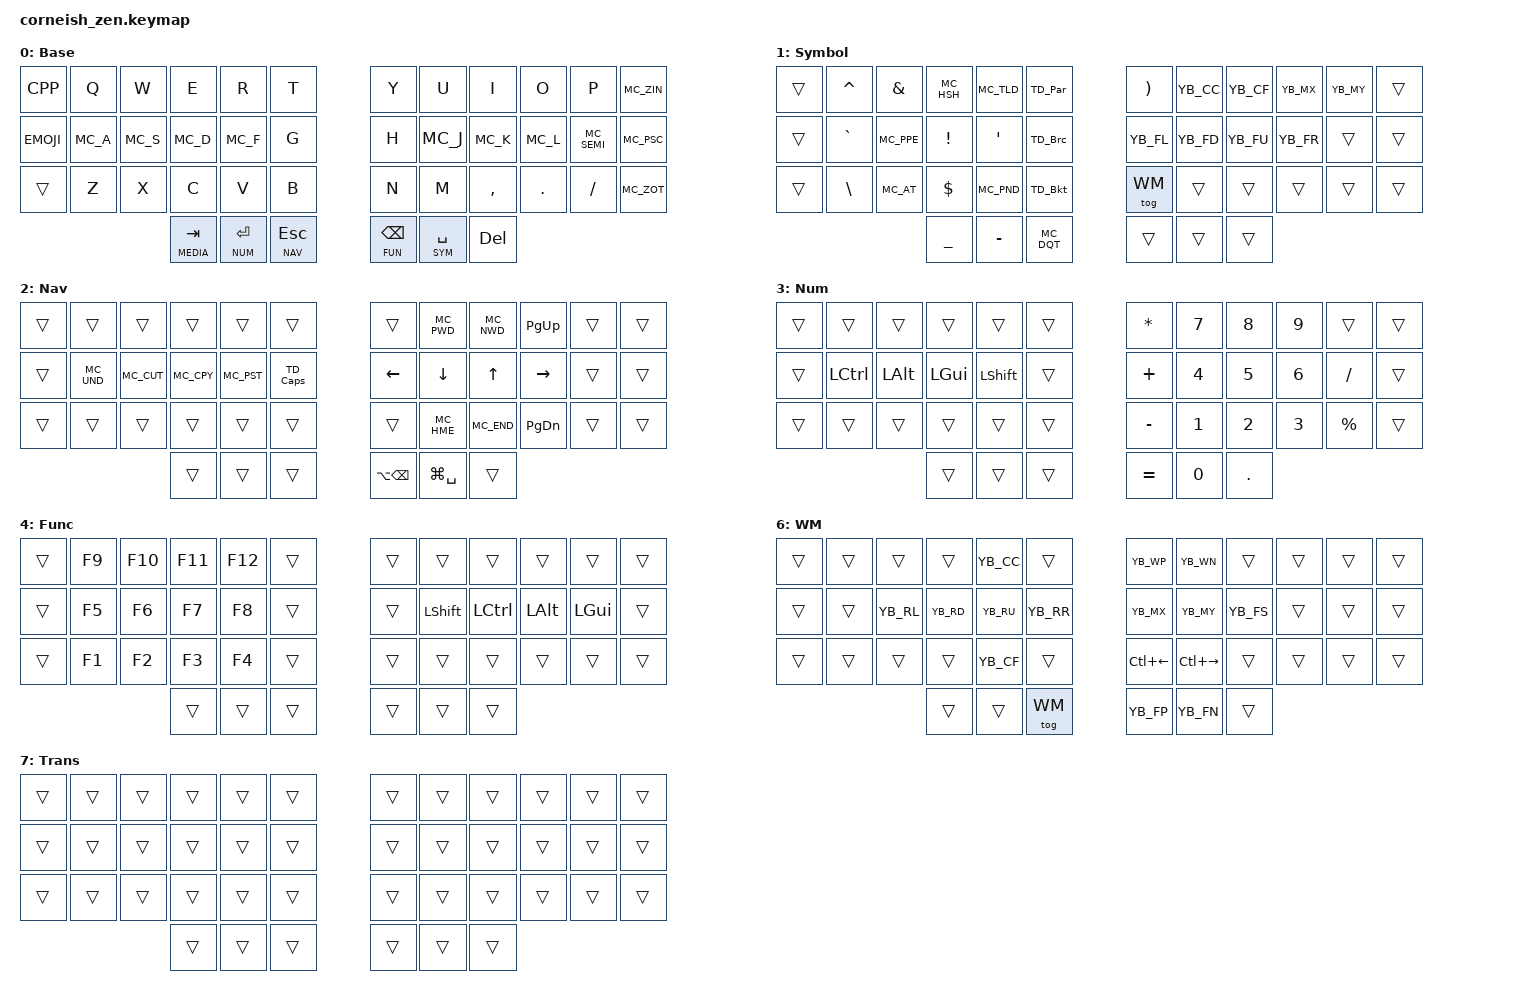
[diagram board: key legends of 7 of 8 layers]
/*
 * Copyright (c) 2020 The ZMK Contributors
 *
 * SPDX-License-Identifier: MIT
 */

#include <behaviors.dtsi>
#include <dt-bindings/zmk/keys.h>
#include <dt-bindings/zmk/bt.h>
#include "layer_names.h"
#include "kp_mac.h"
#include "kp_media.h"

#define ____ &trans
#define FLASH bootloader

/ {
  chosen {
    zmk,matrix_transform = &default_transform;
  };
};

/ {
        keymap {
                compatible = "zmk,keymap";

                base_layer {
                        label = "Base";
// -----------------------------------------------------------------------------------------
// |      |  Q  |  W  |  E  |  R  |  T  |   |  Y  |  U   |  I  |  O  |  P  |      |
// |      |  A  |  S  |  D  |  F  |  G  |   |  H  |  J   |  K  |  L  |  ;  |      |
// |      |  Z  |  X  |  C  |  V  |  B  |   |  N  |  M   |  ,  |  .  |  /  |      |
//                    | TAB | RET | ESC |   | BSP | SPC  | DEL |
                        bindings = <
   &CPP   &kp Q   &kp W  &kp E          &kp R        &kp T        /**/  &kp Y         &kp U        &kp I      &kp O    &kp P     &MC_ZIN
   &EMOJI &MC_A   &MC_S  &MC_D          &MC_F        &kp G        /**/  &kp H         &MC_J        &MC_K      &MC_L    &MC_SEMI  &MC_PSC
   ____   &kp Z   &kp X  &kp C          &kp V        &kp B        /**/  &kp N         &kp M        &kp COMMA  &kp DOT  &kp FSLH  &MC_ZOT
                         &lt MEDIA TAB  &lt NUM RET  &lt NAV ESC  /**/  &lt FUN BSPC  &lt SYM SPC  &kp DEL
                        >;
                };

                symbol_layer {
                        label="Symbol";

// -----------------------------------------------------------------------------------------
// |      | HAT |  &  |  #  |  ~  |  (  |   |  )  | Ctr | Flt | mx  | my  |      |
// |      |  `  |  |  |  !  |   ' |  {  |   | wfl | wfd | wfu | wfr |     |      |
// |      |BSLH |  @  |  $  |  £  |  [  |   | wm  |     |     |     |     |      |
//                    |  _  |  -  |  "  |   |     |     |     |
                        bindings = <
   ____  &kp CARET   &kp AMPS &MC_HSH   &MC_TLD   &TD_Par   /**/    &kp RPAR &YB_CC &YB_CF &YB_MX &YB_MY  ____
   ____  &kp GRAVE   &MC_PPE  &kp EXCL  &kp SQT   &TD_Brc   /**/    &YB_FL   &YB_FD &YB_FU &YB_FR ____    ____
   ____  &kp BSLH    &MC_AT   &kp DLLR  &MC_PND   &TD_Bkt   /**/    &tog WM  ____   ____   ____   ____    ____
                              &kp UNDER &kp MINUS &MC_DQT   /**/    ____     ____   ____
                        >;
                };

                nav_layer {
                        label="Nav";
// -----------------------------------------------------------------------------------------
// |      |     |     |     |     |     |   |SwApp| Pwd  | Nwd | PGUP|     |      |
// |      |UNDO | CUT | COPY|PASTE|CAPS |   |  <  |  v   |  ^  |  >  |     |      |
// |      |     |     |     |     |     |   |SwWin| Home | End | PgDN|     |      |
//                    |     |     |     |   |     | Spot |     |
                        bindings = <
   ____    ____    ____    ____    ____    ____       /**/    ____          &MC_PWD     &MC_NWD  &kp PG_UP  ____  ____
   ____    &MC_UND &MC_CUT &MC_CPY &MC_PST &TD_Caps   /**/    &kp LEFT      &kp DOWN    &kp UP   &kp RIGHT  ____  ____
   ____    ____    ____    ____    ____    ____       /**/    ____          &MC_HME     &MC_END  &kp PG_DN  ____  ____
                           ____    ____    ____       /**/    &kp LA(BSPC)  &kp LG(SPC) ____
                        >;
                };

                num_layer {
                        label="Num";
// -----------------------------------------------------------------------------------------
// |      |     |     |     |     |     |   |  *  |  7   |  8  |  9  |     |      |
// |      | CTRL| ALT | GUI | SHFT|     |   |  +  |  4   |  5  |  6  |  /  |      |
// |      |     |     |     |     |     |   |  -  |  1   |  2  |  3  |  %  |      |
//                    |     |     |     |   |  =  |  0   |  .  |
                        bindings = <
   ____    ____      ____      ____      ____       ____    /**/    &kp STAR  &kp N7  &kp N8  &kp N9  ____      ____
   ____    &kp LCTRL &kp LALT  &kp LGUI  &kp LSHFT  ____    /**/    &kp PLUS  &kp N4  &kp N5  &kp N6  &kp FSLH  ____
   ____    ____      ____      ____      ____       ____    /**/    &kp MINUS &kp N1  &kp N2  &kp N3  &kp PRCNT ____
                               ____      ____       ____    /**/    &kp EQUAL &kp N0  &kp DOT
                        >;
                };

                fun_layer {
                        label="Func";
// -----------------------------------------------------------------------------------------
// |      |     | F9  | F10 | F11 | F12 |   |     |      |     |     |     |      |
// |      |     | F5  |  F6 |  F7 |  F8 |   |     |      |     |     |     |      |
// |      |     | F1  |  F2 |  F3 |  F4 |   |     |      |     |     |     |      |
//                    |     |     |     |   |     |      |     |
                        bindings = <
   ____   &kp F9  &kp F10 &kp F11 &kp F12 ____   /**/   ____    ____      ____      ____     ____     ____
   ____   &kp F5  &kp F6  &kp F7  &kp F8  ____   /**/   ____    &kp LSHFT &kp LCTRL &kp LALT &kp LGUI ____
   ____   &kp F1  &kp F2  &kp F3  &kp F4  ____   /**/   ____    ____      ____      ____     ____     ____
                          ____    ____    ____   /**/   ____    ____      ____
                        >;
                };

                media_layer {
                        label="Media";
// -----------------------------------------------------------------------------------------
// | FLASH|     |     |     |     |     |   |     |      |     |     |     |      |
// |      |     |     |     |     |     |   |     |  <<  |  ^  |  v  |  >> |      |
// |BTCLR | BT0 | BT1 | BT2 |     |     |   |     |      |     |     |     |      |
//                    |     |     |     |   |Mute | Play | Stop|
                        bindings = <
   &FLASH ____   ____   ____   ____   ____   /**/    ____   ____  ____   ____  ____  ____
   ____   ____   ____   ____   ____   ____   /**/    ____   &CPRV  &CVDN  &CVUP  &CNXT  ____
   &BTCLR &BT0   &BT1   &BT2   ____   ____   /**/    ____   ____  ____   ____  ____
                        ____   ____   ____   /**/    &MUTE  &CPP  &STOP
                        >;
                };

                wm_layer {
                        label="WM";
// -----------------------------------------------------------------------------------------
// |      |     |     |     |Centr|     |   |WarpP|WarpN|     |     |     |      |
// |      |     |RSizL|RSizD|RSizU|RSizR|   |FlipX|FlipY|FulSc|     |     |      |
// |      |     |     |     |Float|     |   |SP L |SP R |     |     |     |      |
//                    |     |     | TOG |   |Foc P|Foc N|     |
                        bindings = <
   ____    ____    ____   ____    &YB_CC  ____     /**/  &YB_WP        &YB_WN        ____    ____    ____   ____
   ____    ____    &YB_RL &YB_RD  &YB_RU  &YB_RR   /**/  &YB_MX        &YB_MY        &YB_FS  ____    ____   ____
   ____    ____    ____   ____    &YB_CF  ____     /**/  &kp LC(LEFT)  &kp LC(RIGHT) ____    ____    ____   ____
                          ____    ____    &tog WM  /**/  &YB_FP        &YB_FN        ____
                        >;
                };

                trans_layer {
                        label="Trans";
// -----------------------------------------------------------------------------------------
// |      |     |     |     |     |     |   |     |      |     |     |     |      |
// |      |     |     |     |     |     |   |     |      |     |     |     |      |
// |      |     |     |     |     |     |   |     |      |     |     |     |      |
//                    |     |     |     |   |     |      |     |
                        bindings = <
   ____    ____    ____    ____    ____    ____    /**/    ____         ____           ____    ____    ____    ____
   ____    ____    ____    ____    ____    ____    /**/    ____         ____           ____    ____    ____    ____
   ____    ____    ____    ____    ____    ____    /**/    ____         ____           ____    ____    ____    ____
                           ____    ____    ____    /**/    ____         ____           ____
                        >;
                };

        };
};

#define U_TAPPING_TERM 220

/ {
  behaviors {
    hm: homerow_mods {
      compatible = "zmk,behavior-hold-tap";
      label = "HOMEROW_MODS";
      #binding-cells = <2>;
      tapping_term_ms = <U_TAPPING_TERM>;
      flavor = "tap-preferred";
      bindings = <&kp>, <&kp>;
    };

    caps_word: behavior_caps_word {
      compatible = "zmk,behavior-caps-word";
      label = "CAPS_WORD";
      #binding-cells = <0>;
      continue-list = <UNDERSCORE MINUS BSPC>;
    };

    TD_Caps: td_caps {
        compatible = "zmk,behavior-tap-dance";
        label = "TD_CAPS";
        #binding-cells = <0>;
        tapping-term-ms = <200>;
        bindings = <&caps_word>, <&kp CAPS>;
    };

    TD_Par: td_paren {
        compatible = "zmk,behavior-tap-dance";
        label = "TD_PAREN";
        #binding-cells = <0>;
        tapping-term-ms = <200>;
        bindings = <&kp LPAR>, <&kp RPAR>;
    };

    TD_Brc: td_brace {
        compatible = "zmk,behavior-tap-dance";
        label = "TD_BRACE";
        #binding-cells = <0>;
        tapping-term-ms = <200>;
        bindings = <&kp LBRC>, <&kp RBRC>;
    };

    TD_Bkt: td_bracket {
        compatible = "zmk,behavior-tap-dance";
        label = "TD_BRACKET";
        #binding-cells = <0>;
        tapping-term-ms = <200>;
        bindings = <&kp LBKT>, <&kp RBKT>;
    };

/*
    SW_APP: switch_application {
      compatible = "zmk,behavior-tri-state";
      label = "SWITCH_APP";
      #binding-cells = <0>;
      bindings = <&kt LGUI>, <&kp TAB>, <&kt LGUI>;
    };
*/
    SW_WIN: switch_window {
      compatible = "zmk,behavior-tri-state";
      label = "SWITCH_WIN";
      #binding-cells = <0>;
      bindings = <&kt LGUI>, <&kp GRAVE>, <&kt LGUI>;
    };

  };
};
